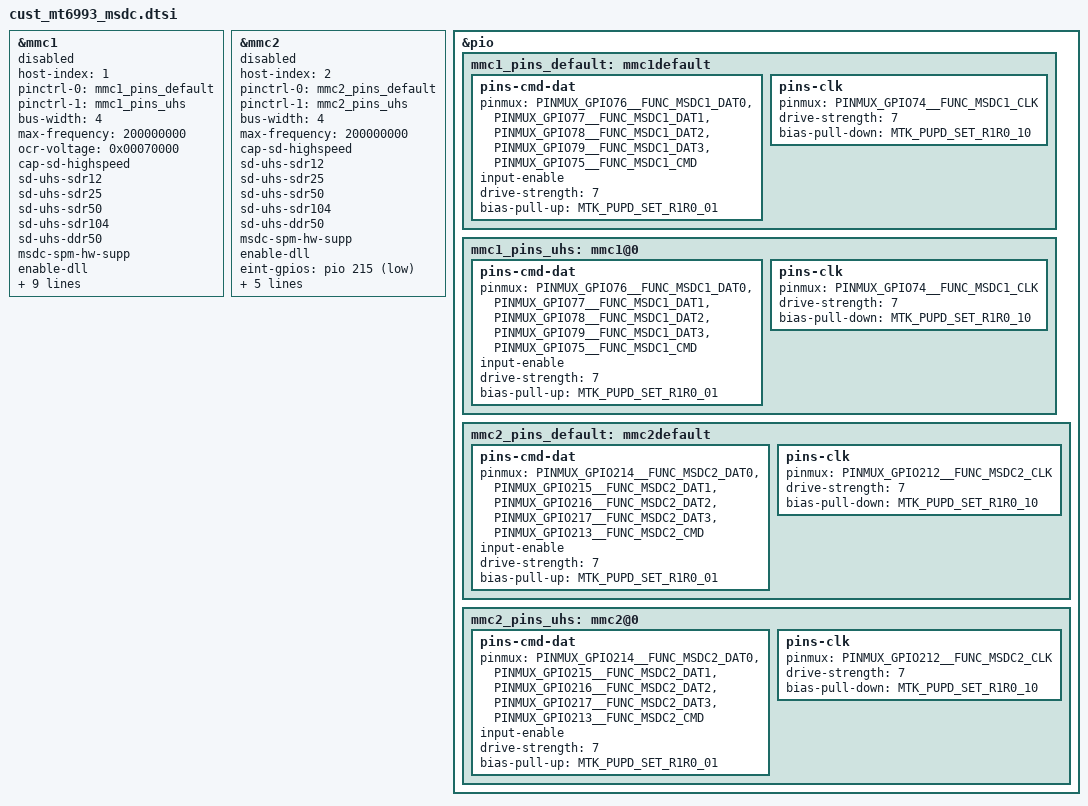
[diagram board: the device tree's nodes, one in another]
// SPDX-License-Identifier: GPL-2.0
/*
 * Copyright (c) 2024 MediaTek Inc.
 */
/********************************************
 * MT6993 MSDC DTSI File
 ********************************************/
#include <dt-bindings/gpio/gpio.h>
#include <dt-bindings/interconnect/mtk,emi.h>

&mmc1 {
	host-index = <1>;
	/* #ifdef OPLUS_FEATRUE_SIM_DETECT add for dx5 ir */
	/* status = "okay"; */
	status = "disabled";
	/* #endif OPLUS_FEATRUE_SIM_DETECT */
	pinctrl-names = "default", "state_uhs", "pull_down";
	pinctrl-0 = <&mmc1_pins_default>;
	pinctrl-1 = <&mmc1_pins_uhs>;
	bus-width = <4>;
	max-frequency = <200000000>;
	ocr-voltage = <0x00070000>;
	cap-sd-highspeed;
	sd-uhs-sdr12;
	sd-uhs-sdr25;
	sd-uhs-sdr50;
	sd-uhs-sdr104;
	sd-uhs-ddr50;
	msdc-spm-hw-supp;
	enable-dll;
	cd-debounce-delay-ms = <0>;
	cd-gpios = <&pio 50 GPIO_ACTIVE_LOW>;
	cd-gpio-num = <50>;
	/* #ifdef OPLUS_FEATURE_CAMERA_COMMON */
	// vmmc-supply = <&mt6661_5_ldc0_4_eint_high>;
	/* #endif OPLUS_FEATURE_CAMERA_COMMON */
	/* #ifdef OPLUS_FEATURE_CONSUMERIR add for dx5 ir */
	// vqmmc-supply = <&mt6661_5_ldc0_3>;
	/* #endif OPLUS_FEATURE_CONSUMERIR */
	no-mmc;
	no-sdio;
	mediatek,mmc-qos;
	interconnects = <&dvfsrc MT6873_MASTER_UFS &dvfsrc MT6873_SLAVE_DDR_EMI>;
	interconnect-names = "msdc-perf-bw";
	required-opps = <&dvfsrc_freq_opp7>;
};

&mmc2 {
	host-index = <2>;
	status = "disabled";
	pinctrl-names = "default", "state_uhs";
	pinctrl-0 = <&mmc2_pins_default>;
	pinctrl-1 = <&mmc2_pins_uhs>;
	bus-width = <4>;
	max-frequency = <200000000>;
	cap-sd-highspeed;
	sd-uhs-sdr12;
	sd-uhs-sdr25;
	sd-uhs-sdr50;
	sd-uhs-sdr104;
	sd-uhs-ddr50;
	msdc-spm-hw-supp;
	enable-dll;
	eint-gpios = <&pio 215 GPIO_ACTIVE_LOW>;
	/* #ifdef OPLUS_FEATURE_CAMERA_COMMON */
	// vmmc-supply = <&mt6661_5_ldc0_4_eint_high>;
	/* #endif OPLUS_FEATURE_CAMERA_COMMON */
	vqmmc-supply = <&mt6661_3_lnc0_10>;
	no-mmc;
	no-sd;
	cap-sdio-irq;
	non-removable;
};

&pio {
	mmc1_pins_default: mmc1default {
		pins-cmd-dat {
			pinmux = <PINMUX_GPIO76__FUNC_MSDC1_DAT0>,
				<PINMUX_GPIO77__FUNC_MSDC1_DAT1>,
				<PINMUX_GPIO78__FUNC_MSDC1_DAT2>,
				<PINMUX_GPIO79__FUNC_MSDC1_DAT3>,
				<PINMUX_GPIO75__FUNC_MSDC1_CMD>;
			input-enable;
			drive-strength = <7>;
			bias-pull-up = <MTK_PUPD_SET_R1R0_01>;
		};

		pins-clk {
			pinmux = <PINMUX_GPIO74__FUNC_MSDC1_CLK>;
			drive-strength = <7>;
			bias-pull-down = <MTK_PUPD_SET_R1R0_10>;
		};
	};
	mmc1_pins_uhs: mmc1@0{
		pins-cmd-dat {
			pinmux = <PINMUX_GPIO76__FUNC_MSDC1_DAT0>,
				<PINMUX_GPIO77__FUNC_MSDC1_DAT1>,
				<PINMUX_GPIO78__FUNC_MSDC1_DAT2>,
				<PINMUX_GPIO79__FUNC_MSDC1_DAT3>,
				<PINMUX_GPIO75__FUNC_MSDC1_CMD>;
			input-enable;
			drive-strength = <7>;
			bias-pull-up = <MTK_PUPD_SET_R1R0_01>;
		};

		pins-clk {
			pinmux = <PINMUX_GPIO74__FUNC_MSDC1_CLK>;
			drive-strength = <7>;
			bias-pull-down = <MTK_PUPD_SET_R1R0_10>;
		};
	};
	mmc2_pins_default: mmc2default {
		pins-cmd-dat {
			pinmux = <PINMUX_GPIO214__FUNC_MSDC2_DAT0>,
				<PINMUX_GPIO215__FUNC_MSDC2_DAT1>,
				<PINMUX_GPIO216__FUNC_MSDC2_DAT2>,
				<PINMUX_GPIO217__FUNC_MSDC2_DAT3>,
				<PINMUX_GPIO213__FUNC_MSDC2_CMD>;
			input-enable;
			drive-strength = <7>;
			bias-pull-up = <MTK_PUPD_SET_R1R0_01>;
		};
		pins-clk {
			pinmux = <PINMUX_GPIO212__FUNC_MSDC2_CLK>;
			drive-strength = <7>;
			bias-pull-down = <MTK_PUPD_SET_R1R0_10>;
		};
	};
	mmc2_pins_uhs: mmc2@0{
		pins-cmd-dat {
			pinmux = <PINMUX_GPIO214__FUNC_MSDC2_DAT0>,
				<PINMUX_GPIO215__FUNC_MSDC2_DAT1>,
				<PINMUX_GPIO216__FUNC_MSDC2_DAT2>,
				<PINMUX_GPIO217__FUNC_MSDC2_DAT3>,
				<PINMUX_GPIO213__FUNC_MSDC2_CMD>;
			input-enable;
			drive-strength = <7>;
			bias-pull-up = <MTK_PUPD_SET_R1R0_01>;
		};
		pins-clk {
			pinmux = <PINMUX_GPIO212__FUNC_MSDC2_CLK>;
			drive-strength = <7>;
			bias-pull-down = <MTK_PUPD_SET_R1R0_10>;
		};
	};
};


